# STM32H7RSxx register map
File version: 0.1
CPU: CM7 r0p1, little endian, MPU, FPU, 4 interrupt priority bits
Registers are 32-bit, read-write, reset 0x0 unless marked. A register's access mark holds for its fields unless they carry their own. Offsets are from the block's base; [hi:lo] are bit positions.

## WWDG
Base 0x40002C00
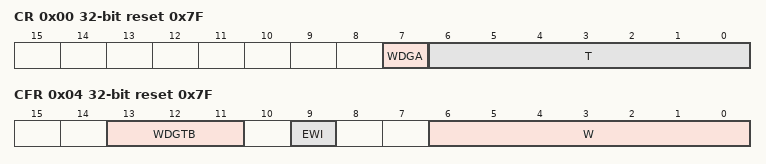
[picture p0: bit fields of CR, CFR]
0x00 CR reset 0x7F — Control register
  [7] WDGA — Activation bit This bit is set by software and only cleared by hardware after a reset. When WDGA=1, the watchdog can generate a reset.
  [6:0] T — 7-bit counter (MSB to LSB) These bits contain the value of the watchdog counter. It is decremented every (4096 x 2WDGTB[1:0]) PCLK cycles. A reset is produced when it is decremented from 0x40 to 0x3F (T6 becomes cleared).
0x04 CFR reset 0x7F — Configuration register
  [13:11] WDGTB — Timer base The time base of the prescaler can be modified as follows:
  [9] EWI — Early wakeup interrupt When set, an interrupt occurs whenever the counter reaches the value 0x40. This interrupt is only cleared by hardware after a reset.
  [6:0] W — 7-bit window value These bits contain the window value to be compared to the downcounter.
0x08 SR — Status register
  [0] EWIF — Early wakeup interrupt flag This bit is set by hardware when the counter has reached the value 0x40. It must be cleared by software by writing 0. A write of 1 has no effect. This bit is also set if the interrupt is not enabled.

## LPUART1 — Universal synchronous asynchronous receiver transmitter
Base 0x58000C00
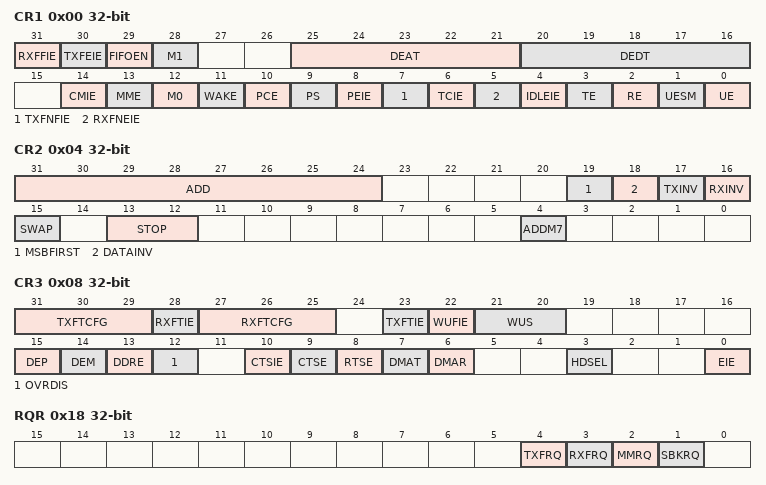
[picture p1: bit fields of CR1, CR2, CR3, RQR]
0x00 CR1 — Control register 1
  [31] RXFFIE
  [30] TXFEIE
  [29] FIFOEN
  [28] M1 — Word length
  [25:21] DEAT
  [20:16] DEDT
  [14] CMIE — Character match interrupt enable
  [13] MME — Mute mode enable
  [12] M0 — Word length
  [11] WAKE — Receiver wakeup method
  [10] PCE — Parity control enable
  [9] PS — Parity selection
  [8] PEIE — PE interrupt enable
  [7] TXFNFIE — TXFIFO not full interrupt enable
  [6] TCIE — Transmission complete interrupt enable
  [5] RXFNEIE
  [4] IDLEIE — IDLE interrupt enable
  [3] TE — Transmitter enable
  [2] RE — Receiver enable
  [1] UESM — USART enable in Stop mode
  [0] UE — USART enable
0x04 CR2 — Control register 2
  [31:24] ADD — Address of the LPUART node
  [19] MSBFIRST — Most significant bit first
  [18] DATAINV — Binary data inversion
  [17] TXINV — TX pin active level inversion
  [16] RXINV — RX pin active level inversion
  [15] SWAP — Swap TX/RX pins
  [13:12] STOP — STOP bits
  [4] ADDM7 — 7-bit Address Detection/4-bit Address Detection
0x08 CR3 — Control register 3
  [31:29] TXFTCFG
  [28] RXFTIE
  [27:25] RXFTCFG
  [23] TXFTIE
  [22] WUFIE — Wakeup from low-power mode interrupt enable
  [21:20] WUS — Wakeup from low-power mode interrupt flag selection
  [15] DEP — Driver enable polarity selection
  [14] DEM — Driver enable mode
  [13] DDRE — DMA Disable on Reception Error
  [12] OVRDIS — Overrun Disable
  [10] CTSIE — CTS interrupt enable
  [9] CTSE — CTS enable
  [8] RTSE — RTS enable
  [7] DMAT — DMA enable transmitter
  [6] DMAR — DMA enable receiver
  [3] HDSEL — Half-duplex selection
  [0] EIE — Error interrupt enable
0x0C BRR — Baud rate register
  [19:0] BRR
0x18 RQR wo — Request register
  [4] TXFRQ
  [3] RXFRQ — Receive data flush request
  [2] MMRQ — Mute mode request
  [1] SBKRQ — Send break request
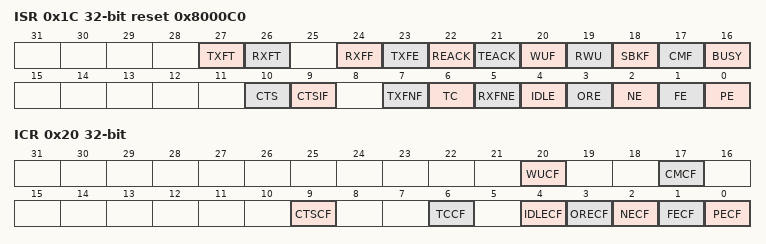
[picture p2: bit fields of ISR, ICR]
0x1C ISR ro reset 0x8000C0 — Interrupt and status register
  [27] TXFT, [26] RXFT, [24] RXFF, [23] TXFE, [22] REACK, [21] TEACK, [20] WUF, [19] RWU, [18] SBKF, [17] CMF, [16] BUSY, [10] CTS, [9] CTSIF, [7] TXFNF, [6] TC, [5] RXFNE, [4] IDLE, [3] ORE, [2] NE, [1] FE, [0] PE
0x20 ICR wo — Interrupt flag clear register
  [20] WUCF — Wakeup from low-power mode clear flag
  [17] CMCF — Character match clear flag
  [9] CTSCF — CTS clear flag
  [6] TCCF — Transmission complete clear flag
  [4] IDLECF — Idle line detected clear flag
  [3] ORECF — Overrun error clear flag
  [2] NECF — Noise detected clear flag
  [1] FECF — Framing error clear flag
  [0] PECF — Parity error clear flag
0x24 RDR ro — Receive data register
  [8:0] RDR — Receive data value
0x28 TDR — Transmit data register
  [8:0] TDR — Transmit data value
0x2C PRESC — prescaler register
  [3:0] PRESCALER
